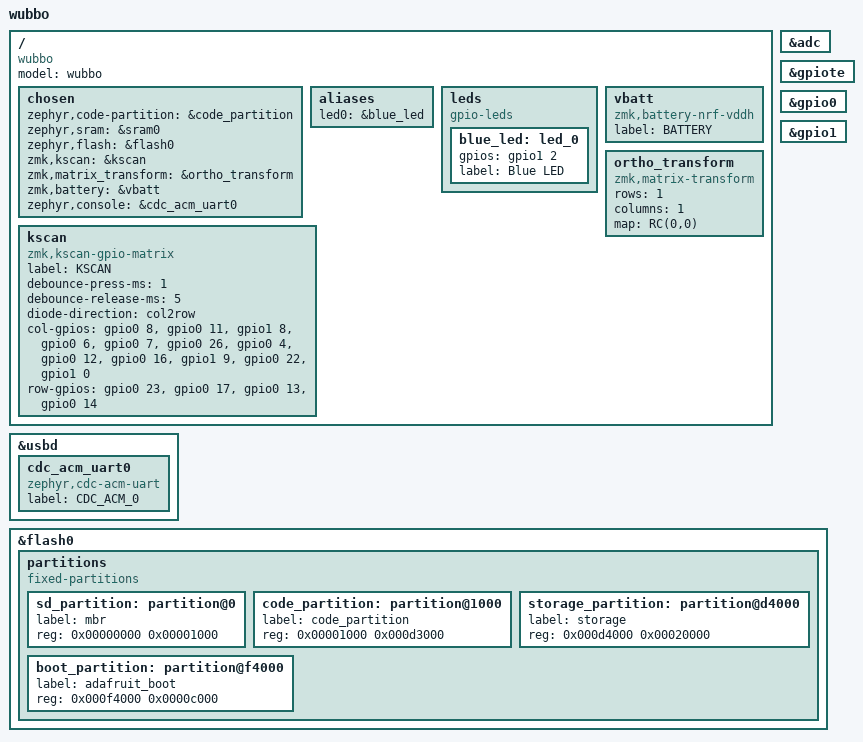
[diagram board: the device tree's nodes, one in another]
/*
 * Copyright (c) 2022 The ZMK Contributors
 *
 * SPDX-License-Identifier: MIT
 */

/dts-v1/;
#include <nordic/nrf52840_qiaa.dtsi>
#include <dt-bindings/zmk/matrix_transform.h>

/ {
	model = "wubbo";
	compatible = "wubbo";

	chosen {
		zephyr,code-partition = &code_partition;
		zephyr,sram = &sram0;
		zephyr,flash = &flash0;
		zmk,kscan = &kscan;
		zmk,matrix_transform = &ortho_transform;
		zmk,battery = &vbatt;
		zephyr,console = &cdc_acm_uart0;
	};

	aliases {
		led0 = &blue_led;
	};

	leds {
		compatible = "gpio-leds";
		blue_led: led_0 {
			gpios = <&gpio1 2 GPIO_ACTIVE_HIGH>;
			label = "Blue LED";
		};
	};

	vbatt: vbatt {
		compatible = "zmk,battery-nrf-vddh";
		label = "BATTERY";
	};

	ortho_transform: ortho_transform {
		compatible = "zmk,matrix-transform";
		rows = <1>;
		columns = <1>;
		map = <
	RC(0,0)
	>;
	};


	
	kscan: kscan {
		compatible = "zmk,kscan-gpio-matrix";
		label = "KSCAN";
		debounce-press-ms = <1>;
		debounce-release-ms = <5>;

		diode-direction = "col2row";

		col-gpios
			= <&gpio0 8 (GPIO_ACTIVE_HIGH)>
			, <&gpio0 11 (GPIO_ACTIVE_HIGH)>
			, <&gpio1 8 (GPIO_ACTIVE_HIGH)>
			, <&gpio0 6 (GPIO_ACTIVE_HIGH)>
			, <&gpio0 7 (GPIO_ACTIVE_HIGH)>
			, <&gpio0 26 (GPIO_ACTIVE_HIGH)>
			, <&gpio0 4 (GPIO_ACTIVE_HIGH)>
			, <&gpio0 12 (GPIO_ACTIVE_HIGH)>
			, <&gpio0 16 (GPIO_ACTIVE_HIGH)>
			, <&gpio1 9 (GPIO_ACTIVE_HIGH)>
			, <&gpio0 22 (GPIO_ACTIVE_HIGH)>
			, <&gpio1 0 (GPIO_ACTIVE_HIGH)>
			;
		row-gpios
			= <&gpio0 23  (GPIO_ACTIVE_HIGH | GPIO_PULL_DOWN)>
			, <&gpio0 17  (GPIO_ACTIVE_HIGH | GPIO_PULL_DOWN)>
			, <&gpio0 13 (GPIO_ACTIVE_HIGH | GPIO_PULL_DOWN)>
			, <&gpio0 14 (GPIO_ACTIVE_HIGH | GPIO_PULL_DOWN)>
			;
	};
};

&adc {
	status = "okay";
};

&gpiote {
	status = "okay";
};

&gpio0 {
	status = "okay";
};

&gpio1 {
	status = "okay";
};


&usbd {
	status = "okay";
	cdc_acm_uart0: cdc_acm_uart0 {
		compatible = "zephyr,cdc-acm-uart";
		label = "CDC_ACM_0";
	};
}; 


&flash0 {
	/*
	 * For more information, see:
	 * http://docs.zephyrproject.org/latest/devices/dts/flash_partitions.html
	 */
	partitions {
		compatible = "fixed-partitions";
		#address-cells = <1>;
		#size-cells = <1>;

		sd_partition: partition@0 {
			label = "mbr";
			reg = <0x00000000 0x00001000>;
		};
		code_partition: partition@1000 {
			label = "code_partition";
			reg = <0x00001000 0x000d3000>;
		};

		storage_partition: partition@d4000 {
			label = "storage";
			reg = <0x000d4000 0x00020000>;
		};

		boot_partition: partition@f4000 {
			label = "adafruit_boot";
			reg = <0x000f4000 0x0000c000>;
		};
	};
};
